# CY8C3246PVI_147 register map
File version: 0.1
CY8C32
Registers are 8-bit, read-write, no defined reset value unless marked. A register's access mark holds for its fields unless they carry their own. Offsets are from the block's base; lines under a group give offsets from that group; [hi:lo] are bit positions; {n}, {i} and the like mark numbered series; 'fields as' and 'values as' point back to an identical list; <NAME> marks a mode.

## Memory map
0x00000000 ADC
0x00000000 MY_TIMER
0x00000000 UART_RS485 — UART
0x00000000 PACER_TIMER
0x0000646C ADC_STATUS
0x00006475 Chip_Select_B
0x0000647B Chip_Select_A
0x0000647C RS485_CTS
0x0000647D FTDI_ENABLE_REG
0x00006565 FF_STATUS
0x00006574 ADC_SOC
0x00006575 RESET_FF

## ADC_STATUS
Base 0x0000646C
0x00 ADC_STATUS_STATUS_REG
0x20 ADC_STATUS_MASK_REG
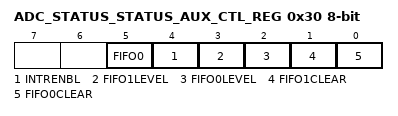
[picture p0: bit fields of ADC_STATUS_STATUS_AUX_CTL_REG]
0x30 ADC_STATUS_STATUS_AUX_CTL_REG
  [5] FIFO0 — FIFO0 clear
    1=ENABLED (Enable counter); 0=DISABLED (Disable counter)
  [4] INTRENBL — Enables or disables the Interrupt
    1=ENABLED (Interrupt enabled); 0=DISABLED (Interrupt disabled)
  [3] FIFO1LEVEL — FIFO level
    1=ENABLED (FIFO LVL: input mode: FIFO at least 1/2 empty; output mode: FIFO at least 1/2 full); 0=DISABLED (FIFO LVL: input mode: FIFO not full; output mode: FIFO not empty)
  [2] FIFO0LEVEL — FIFO level
    values as FIFO1LEVEL
  [1] FIFO1CLEAR — FIFO clear
    1=ENABLED (Clear FIFO state); 0=DISABLED (Normal FIFO operation)
  [0] FIFO0CLEAR — FIFO clear
    values as FIFO1CLEAR

## FF_STATUS
Base 0x00006565
Registers as ADC_STATUS (with ADC_STATUS read as FF_STATUS).

## Chip_Select_B
Base 0x00006475
0x00 Chip_Select_B_CONTROL_REG

## ADC_SOC
Base 0x00006574
Registers as Chip_Select_B (with Chip_Select_B read as ADC_SOC).

## FTDI_ENABLE_REG
Base 0x0000647D
Registers as Chip_Select_B (with Chip_Select_B read as FTDI_ENABLE_REG).

## RESET_FF
Base 0x00006575
Registers as Chip_Select_B (with Chip_Select_B read as RESET_FF).

## RS485_CTS
Base 0x0000647C
Registers as Chip_Select_B (with Chip_Select_B read as RS485_CTS).

## Chip_Select_A
Base 0x0000647B
Registers as Chip_Select_B (with Chip_Select_B read as Chip_Select_A).

## MY_TIMER
Base 0x00000000
0x640C MY_TIMER_COUNTER 24-bit — UDB.A0 - Current Down Counter Value
0x642C MY_TIMER_PERIOD 24-bit — UDB.D0 - Assigned Period
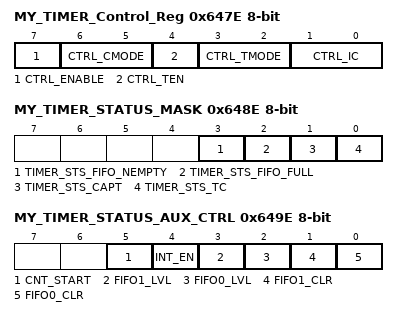
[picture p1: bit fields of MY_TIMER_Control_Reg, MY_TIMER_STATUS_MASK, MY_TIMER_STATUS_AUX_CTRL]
0x647E MY_TIMER_Control_Reg — UDB Control Register - Assigned Control Register Value
  [7] CTRL_ENABLE — Enable the Timer
  [6:5] CTRL_CMODE — Capture Mode
  [4] CTRL_TEN — Trigger Enable Bit
  [3:2] CTRL_TMODE — Trigger Mode
  [1:0] CTRL_IC — Interrupt Count
0x648E MY_TIMER_STATUS_MASK — UDB Status bits Interrupt Mask Enable Register
  [3] TIMER_STS_FIFO_NEMPTY ro — FIFO Empty status
  [2] TIMER_STS_FIFO_FULL ro — FIFO Full Status
  [1] TIMER_STS_CAPT ro — Enables the Interrupt on Capture
  [0] TIMER_STS_TC ro — Enables the Interrupt on TC
0x649E MY_TIMER_STATUS_AUX_CTRL — UDB Auxilliary Control Register
  [5] CNT_START — FIFO0 clear
    0=E_CNT_START0 (Disable counter); 1=E_CNT_START1 (Enable counter)
  [4] INT_EN
    0=E_INT_EN0 (Interrupt disabled); 1=E_INT_EN1 (Interrupt enabled)
  [3] FIFO1_LVL — FIFO level
    0=E_FIFO_LVL_0 (FIFO LVL: input mode: FIFO not full; output mode: FIFO not empty); 1=E_FIFO_LVL_1 (FIFO LVL: input mode: FIFO at least 1/2 empty; output mode: FIFO at least 1/2 full)
  [2] FIFO0_LVL — FIFO level
    values as FIFO1_LVL
  [1] FIFO1_CLR — FIFO1 clear
    0=E_FIFO_CLR_0 (Normal FIFO operation); 1=E_FIFO_CLR_1 (Clear FIFO state)
  [0] FIFO0_CLR — FIFO0 clear
    values as FIFO1_CLR

## UART_RS485 — UART
Base 0x00000000
0x6423 RX_UART_RS485_RX_ADDRESS1 — RX Address1 Register
0x6433 RX_UART_RS485_RX_ADDRESS2 — RX Address2 Register
0x6443 RX_UART_RS485_RX_DATA — RX Data Register
0x6445 TX_UART_RS485_TX_DATA — TX Data Register
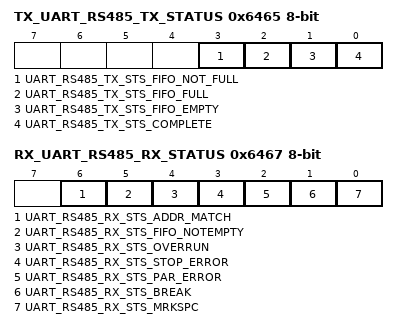
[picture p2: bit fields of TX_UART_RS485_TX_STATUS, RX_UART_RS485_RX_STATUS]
0x6465 TX_UART_RS485_TX_STATUS — TX status register
  [3] UART_RS485_TX_STS_FIFO_NOT_FULL ro, [2] UART_RS485_TX_STS_FIFO_FULL ro, [1] UART_RS485_TX_STS_FIFO_EMPTY ro, [0] UART_RS485_TX_STS_COMPLETE ro
0x6467 RX_UART_RS485_RX_STATUS — RX status register
  [6] UART_RS485_RX_STS_ADDR_MATCH ro, [5] UART_RS485_RX_STS_FIFO_NOTEMPTY ro, [4] UART_RS485_RX_STS_OVERRUN ro, [3] UART_RS485_RX_STS_STOP_ERROR ro, [2] UART_RS485_RX_STS_PAR_ERROR ro, [1] UART_RS485_RX_STS_BREAK ro, [0] UART_RS485_RX_STS_MRKSPC ro
